# ESP32 register map
Vendor: ESPRESSIF SYSTEMS (SHANGHAI) CO., LTD.; Series: ESP32 Series; File version: 17
CPU: Xtensa LX6 r0p0, little endian, no MPU, FPU, 0 interrupt priority bits
Address unit: 32 bits
Registers are 32-bit, read-write, reset 0x0 unless marked. A register's access mark holds for its fields unless they carry their own. Offsets are from the block's base; [hi:lo] are bit positions; {n}, {i} and the like mark numbered series; 'fields as' and 'values as' point back to an identical list.

## GPIO — General Purpose Input/Output
Base 0x3FF44000
0x00 BT_SELECT
  [31:0] BT_SEL
0x04 OUT
  [31:0] DATA — GPIO0~31 output value
0x08 OUT_W1TS
  [31:0] OUT_DATA_W1TS — GPIO0~31 output value write 1 to set
0x0C OUT_W1TC
  [31:0] OUT_DATA_W1TC — GPIO0~31 output value write 1 to clear
0x10 OUT1
  [7:0] DATA — GPIO32~39 output value
0x14 OUT1_W1TS
  [7:0] OUT1_DATA_W1TS — GPIO32~39 output value write 1 to set
0x18 OUT1_W1TC
  [7:0] OUT1_DATA_W1TC — GPIO32~39 output value write 1 to clear
0x1C SDIO_SELECT
  [7:0] SDIO_SEL — SDIO PADS on/off control from outside
0x20 ENABLE
  [31:0] DATA — GPIO0~31 output enable
0x24 ENABLE_W1TS
  [31:0] ENABLE_DATA_W1TS — GPIO0~31 output enable write 1 to set
0x28 ENABLE_W1TC
  [31:0] ENABLE_DATA_W1TC — GPIO0~31 output enable write 1 to clear
0x2C ENABLE1
  [7:0] DATA — GPIO32~39 output enable
0x30 ENABLE1_W1TS
  [7:0] ENABLE1_DATA_W1TS — GPIO32~39 output enable write 1 to set
0x34 ENABLE1_W1TC
  [7:0] ENABLE1_DATA_W1TC — GPIO32~39 output enable write 1 to clear
0x38 STRAP ro
  [15:0] STRAPPING — {10'b0, MTDI, GPIO0, GPIO2, GPIO4, MTDO, GPIO5}
0x3C IN ro
  [31:0] DATA — GPIO0~31 input value
0x40 IN1 ro
  [7:0] DATA — GPIO32~39 input value
0x44 STATUS
  [31:0] INT — GPIO0~31 interrupt status
0x48 STATUS_W1TS
  [31:0] STATUS_INT_W1TS — GPIO0~31 interrupt status write 1 to set
0x4C STATUS_W1TC
  [31:0] STATUS_INT_W1TC — GPIO0~31 interrupt status write 1 to clear
0x50 STATUS1
  [7:0] INT — GPIO32~39 interrupt status
0x54 STATUS1_W1TS
  [7:0] STATUS1_INT_W1TS — GPIO32~39 interrupt status write 1 to set
0x58 STATUS1_W1TC
  [7:0] STATUS1_INT_W1TC — GPIO32~39 interrupt status write 1 to clear
0x60 ACPU_INT ro
  [31:0] APPCPU_INT — GPIO0~31 APP CPU interrupt status
0x64 ACPU_NMI_INT ro
  [31:0] APPCPU_NMI_INT — GPIO0~31 APP CPU non-maskable interrupt status
0x68 PCPU_INT ro
  [31:0] PROCPU_INT — GPIO0~31 PRO CPU interrupt status
0x6C PCPU_NMI_INT ro
  [31:0] PROCPU_NMI_INT — GPIO0~31 PRO CPU non-maskable interrupt status
0x70 CPUSDIO_INT ro
  [31:0] SDIO_INT — SDIO's extent GPIO0~31 interrupt
0x74 ACPU_INT1 ro
  [7:0] APPCPU_INT_H — GPIO32~39 APP CPU interrupt status
0x78 ACPU_NMI_INT1 ro
  [7:0] APPCPU_NMI_INT_H — GPIO32~39 APP CPU non-maskable interrupt status
0x7C PCPU_INT1 ro
  [7:0] PROCPU_INT_H — GPIO32~39 PRO CPU interrupt status
0x80 PCPU_NMI_INT1 ro
  [7:0] PROCPU_NMI_INT_H — GPIO32~39 PRO CPU non-maskable interrupt status
0x84 CPUSDIO_INT1 access per field
  [17:13] PIN_INT_ENA rw
  [12:11] PIN_CONFIG rw
  [10] PIN_WAKEUP_ENABLE rw
  [9:7] PIN_INT_TYPE rw
  [2] PIN_PAD_DRIVER rw
  [7:0] SDIO_INT_H ro — SDIO's extent GPIO32~39 interrupt
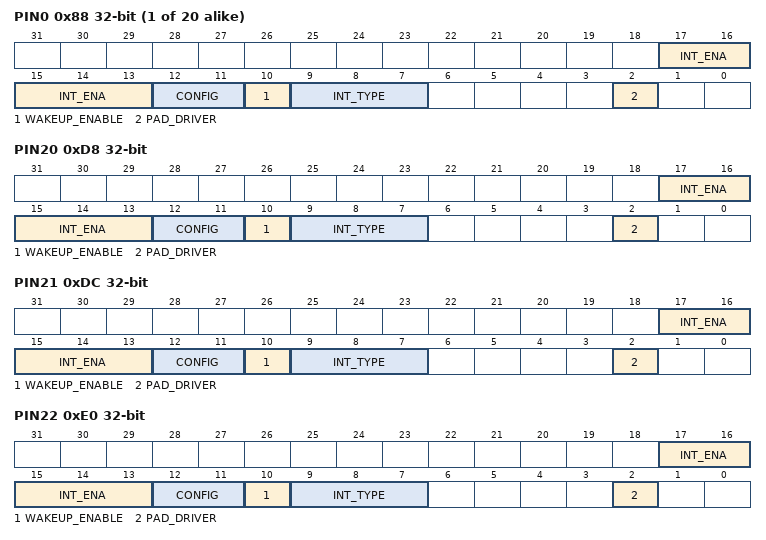
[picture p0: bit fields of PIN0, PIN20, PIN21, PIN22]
{0x88+4i} PIN{i} (i=0..19)
  [17:13] INT_ENA — bit0: APP CPU interrupt enable bit1: APP CPU non-maskable interrupt enable bit3: PRO CPU interrupt enable bit4: PRO CPU non-maskable interrupt enable bit5: SDIO's extent interrupt enable
  [12:11] CONFIG
  [10] WAKEUP_ENABLE — GPIO wake up enable only available in light sleep
  [9:7] INT_TYPE — if set to 0: GPIO interrupt disable if set to 1: rising edge trigger if set to 2: falling edge trigger if set to 3: any edge trigger if set to 4: low level trigger if set to 5: high level trigger
  [2] PAD_DRIVER — if set to 0: normal output if set to 1: open drain
0xD8 PIN20
  [17:13] INT_ENA — bit0: APP CPU interrupt enable bit1: APP CPU non-mask interrupt enable bit3: PRO CPU interrupt enable bit4: PRO CPU non-mask interrupt enable bit5: SDIO's extent interrupt enable
  [12:11] CONFIG
  [10] WAKEUP_ENABLE — GPIO wake up enable only available in light sleep
  [9:7] INT_TYPE — if set to 0: GPIO interrupt disable if set to 1: rising edge trigger if set to 2: falling edge trigger if set to 3: any edge trigger if set to 4: low level trigger if set to 5: high level trigger
  [2] PAD_DRIVER — if set to 0: normal output if set to 1: open drain
0xDC PIN21
  fields as PIN0
0xE0 PIN22
  [17:13] INT_ENA
  [12:11] CONFIG — bit0: APP CPU interrupt enable bit1: APP CPU non-maskable interrupt enable bit3: PRO CPU interrupt enable bit4: PRO CPU non-maskable interrupt enable bit5: SDIO's extent interrupt enable
  [10] WAKEUP_ENABLE
  [9:7] INT_TYPE — GPIO wake up enable only available in light sleep
  [2] PAD_DRIVER
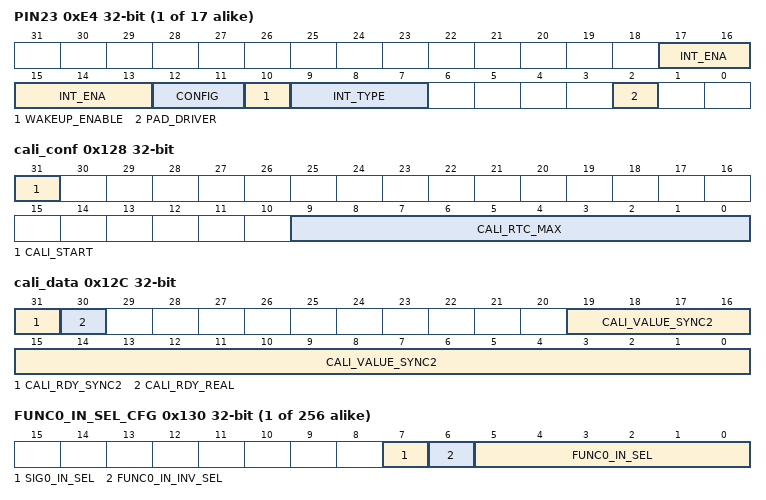
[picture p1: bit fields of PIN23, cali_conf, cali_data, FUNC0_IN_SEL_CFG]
{0x88+4i} PIN{i} (i=23..39)
  fields as PIN0
0x128 cali_conf
  [31] CALI_START, [9:0] CALI_RTC_MAX
0x12C cali_data ro
  [31] CALI_RDY_SYNC2, [30] CALI_RDY_REAL, [19:0] CALI_VALUE_SYNC2
{0x130+4i} FUNC{i}_IN_SEL_CFG (i=0..255)
  [7] SIG{i}_IN_SEL — if the slow signal bypass the io matrix or not if you want setting the value to 1
  [6] FUNC{i}_IN_INV_SEL — revert the value of the input if you want to revert please set the value to 1
  [5:0] FUNC{i}_IN_SEL — select one of the 256 inputs
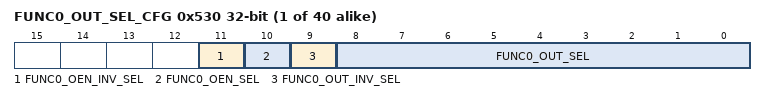
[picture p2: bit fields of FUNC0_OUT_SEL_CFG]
{0x530+4i} FUNC{i}_OUT_SEL_CFG (i=0..39)
  [11] FUNC{i}_OEN_INV_SEL — invert the output enable value if you want to revert the output enable value setting the value to 1
  [10] FUNC{i}_OEN_SEL — weather using the logical oen signal or not using the value setting by the register
  [9] FUNC{i}_OUT_INV_SEL — invert the output value if you want to revert the output value setting the value to 1
  [8:0] FUNC{i}_OUT_SEL — select one of the 256 output to 40 GPIO
